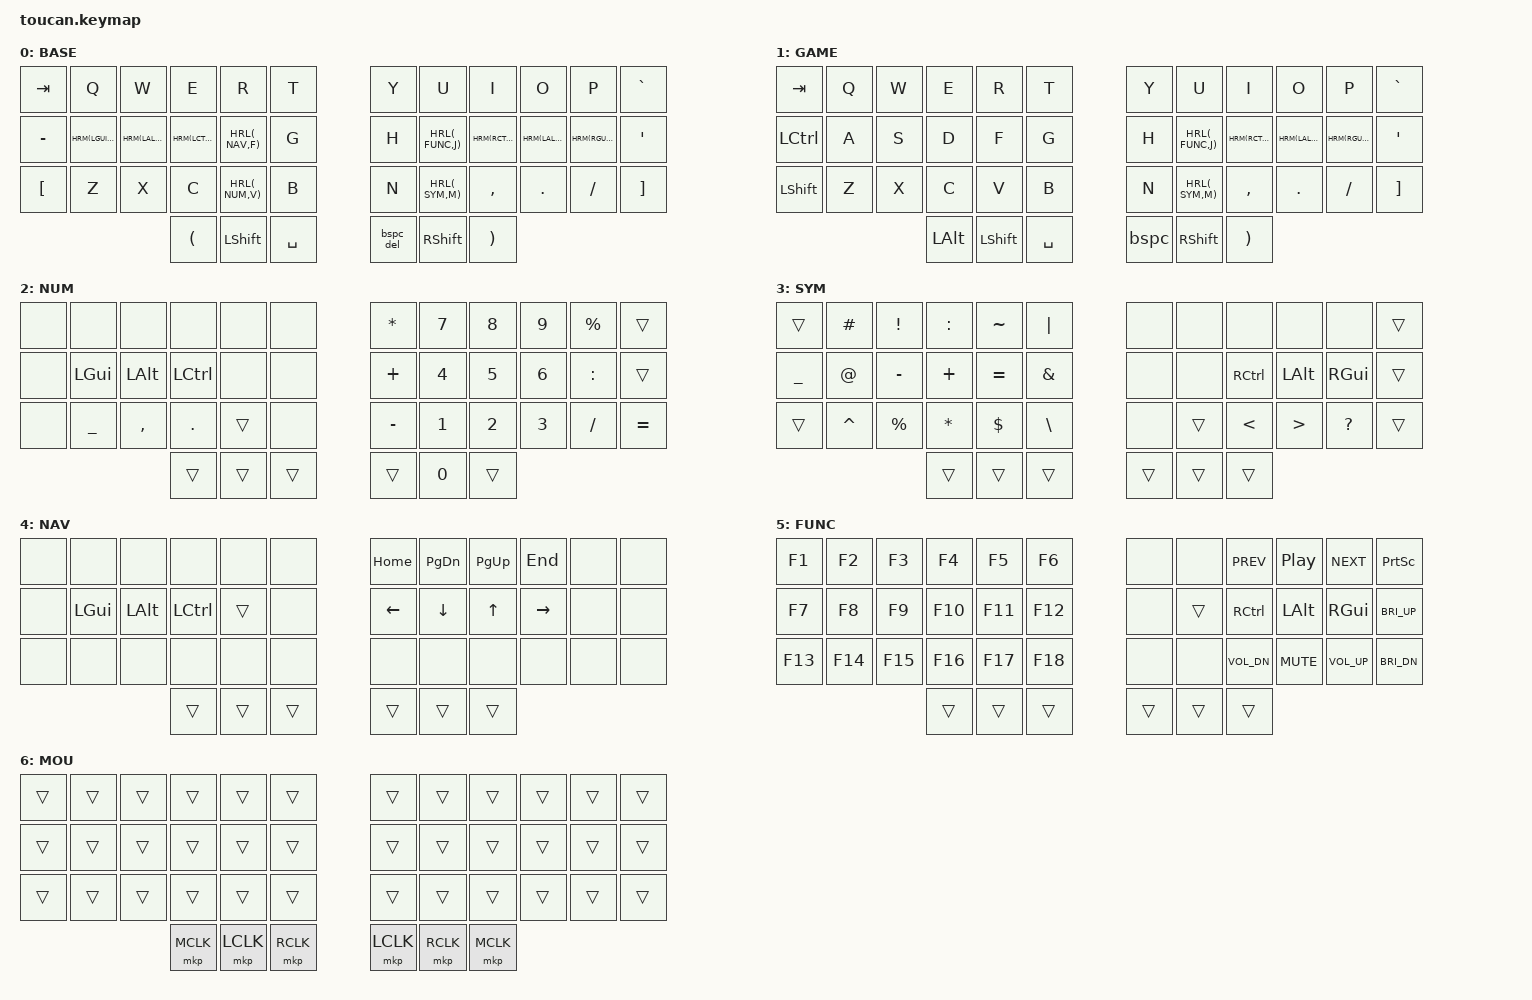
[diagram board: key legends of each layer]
#include <behaviors.dtsi>
#include <dt-bindings/zmk/keys.h>
#include <dt-bindings/zmk/bt.h>
#include <dt-bindings/zmk/outputs.h>
#include <dt-bindings/zmk/pointing.h>

#define _BASE 0
#define _GAM  1
#define _NUM  2
#define _SYM  3
#define _NAV  4
#define _FUNC 5
#define _MOU  6

#define _HRM(m, k) &hrm m k
#define _HRL(l, k) &hrl l k

&caps_word {
    continue-list = <BACKSPACE DELETE UNDERSCORE MINUS>;
};
&lt {
    quick-tap-ms = <170>;
};

/ {
    behaviors {
        bspc_del: backspace_delete {
            compatible = "zmk,behavior-mod-morph";
            #binding-cells = <0>;
            bindings = <&kp BACKSPACE>, <&kp DELETE>;
            mods = <MOD_LSFT>;
        };

        hrm: home_row_mod {
            compatible = "zmk,behavior-hold-tap";
            #binding-cells = <2>;
            flavor = "tap-preferred";
            require-prior-idle-ms = <150>;
            tapping-term-ms = <180>;
            quick-tap-ms = <170>;
            bindings = <&kp>, <&kp>;
            // hold-trigger-key-positions = < ... >; // List of keys on the right side of the keyboard
            // hold-trigger-on-release;
        };
        hrl: home_row_layer {
            compatible = "zmk,behavior-hold-tap";
            #binding-cells = <2>;
            flavor = "tap-preferred";
            require-prior-idle-ms = <150>;
            tapping-term-ms = <180>;
            quick-tap-ms = <170>;
            bindings = <&mo>, <&kp>;
            // hold-trigger-key-positions = < ... >; // List of keys on the right side of the keyboard
            // hold-trigger-on-release;
        };
    };

    // conditional_layers {
    //     compatible = "zmk,conditional-layers";
    //     tri_layer {
    //         if-layers = <1 2>;
    //         then-layer = <3>;
    //     };
    // };

    combos {
        compatible = "zmk,combos";
        combo_esc {
            timeout-ms = <50>;
            require-prior-idle-ms = <100>;
            key-positions = <19 20>;
            bindings = <&kp ESC>;
        };
        combo_ret {
            timeout-ms = <50>;
            require-prior-idle-ms = <100>;
            key-positions = <31 32>;
            bindings = <&kp RET>;
        };
        combo_cw {
            timeout-ms = <50>;
            require-prior-idle-ms = <100>;
            key-positions = <32 33>;
            bindings = <&caps_word>;
        };
        combo_caps {
            timeout-ms = <50>;
            require-prior-idle-ms = <100>;
            key-positions = <33 34>;
            bindings = <&kp CAPS>;
        };
        combo_toggle_game {
            timeout-ms = <50>;
            require-prior-idle-ms = <100>;
            key-positions = <0 5 29>;
            bindings = <&tog 1>;
        };
    };

    keymap {
        compatible = "zmk,keymap";

        base {
            display-name = "BASE";
            bindings = <
//    ┌─────┬──────────────┬──────────────┬──────────────┬──────────────┬─────┐   ┌───────────┬───────────────┬──────────────┬──────────────┬──────────────┬───┐
//    │ tab │      Q       │      W       │      E       │      R       │  T  │   │     Y     │       U       │      I       │      O       │      P       │ ` │
//    ├─────┼──────────────┼──────────────┼──────────────┼──────────────┼─────┤   ├───────────┼───────────────┼──────────────┼──────────────┼──────────────┼───┤
//    │  -  │ _HRM(lgui,A) │ _HRM(lalt,S) │ _HRM(lctl,D) │ _HRL(_NAV,F) │  G  │   │     H     │ _HRL(_FUNC,J) │ _HRM(rctl,K) │ _HRM(lalt,L) │ _HRM(rgui,;) │ ' │
//    ├─────┼──────────────┼──────────────┼──────────────┼──────────────┼─────┤   ├───────────┼───────────────┼──────────────┼──────────────┼──────────────┼───┤
//    │  [  │      Z       │      X       │      C       │ _HRL(_NUM,V) │  B  │   │     N     │ _HRL(_SYM,M)  │      ,       │      .       │      /       │ ] │
//    └─────┴──────────────┴──────────────┼──────────────┼──────────────┼─────┤   ├───────────┼───────────────┼──────────────┼──────────────┴──────────────┴───┘
//                                        │      (       │     lsft     │ spc │   │ &bspc_del │     rsft      │      )       │
//                                        └──────────────┴──────────────┴─────┘   └───────────┴───────────────┴──────────────┘
  &kp TAB     &kp Q          &kp W          &kp E           &kp R          &kp T      &kp Y   &kp U           &kp I           &kp O          &kp P             &kp GRAVE
  &kp MINUS   _HRM(LGUI,A)   _HRM(LALT,S)   _HRM(LCTRL,D)   _HRL(_NAV,F)   &kp G      &kp H   _HRL(_FUNC,J)   _HRM(RCTRL,K)   _HRM(LALT,L)   _HRM(RGUI,SEMI)   &kp SQT
  &kp LBKT    &kp Z          &kp X          &kp C           _HRL(_NUM,V)   &kp B      &kp N   _HRL(_SYM,M)    &kp COMMA       &kp DOT        &kp FSLH          &kp RBKT
  &kp LPAR    &kp LSHFT      &kp SPACE      &bspc_del       &kp RSHFT      &kp RPAR
            >;
        };

        game {
            display-name = "GAME";
            bindings = <
//    ┌──────┬───┬───┬──────┬──────┬─────┐   ┌──────┬───────────────┬────────────────┬──────────────┬──────────────┬───┐
//    │ tab  │ Q │ W │  E   │  R   │  T  │   │  Y   │       U       │       I        │      O       │      P       │ ` │
//    ├──────┼───┼───┼──────┼──────┼─────┤   ├──────┼───────────────┼────────────────┼──────────────┼──────────────┼───┤
//    │ lctl │ A │ S │  D   │  F   │  G  │   │  H   │ _HRL(_FUNC,J) │ _HRM(rctlTL,K) │ _HRM(lalt,L) │ _HRM(rgui,;) │ ' │
//    ├──────┼───┼───┼──────┼──────┼─────┤   ├──────┼───────────────┼────────────────┼──────────────┼──────────────┼───┤
//    │ lsft │ Z │ X │  C   │  V   │  B  │   │  N   │ _HRL(_SYM,M)  │       ,        │      .       │      /       │ ] │
//    └──────┴───┴───┼──────┼──────┼─────┤   ├──────┼───────────────┼────────────────┼──────────────┴──────────────┴───┘
//                   │ lalt │ lsft │ spc │   │ bspc │     rsft      │       )        │
//                   └──────┴──────┴─────┘   └──────┴───────────────┴────────────────┘
  &kp TAB     &kp Q       &kp W       &kp E      &kp R       &kp T      &kp Y   &kp U           &kp I          &kp O          &kp P             &kp GRAVE
  &kp LCTRL   &kp A       &kp S       &kp D      &kp F       &kp G      &kp H   _HRL(_FUNC,J)   _HRM(RCTL,K)   _HRM(LALT,L)   _HRM(RGUI,SEMI)   &kp SQT
  &kp LSHFT   &kp Z       &kp X       &kp C      &kp V       &kp B      &kp N   _HRL(_SYM,M)    &kp COMMA      &kp DOT        &kp FSLH          &kp RBKT
  &kp LALT    &kp LSHFT   &kp SPACE   &kp bspc   &kp RSHFT   &kp RPAR
            >;
        };

        num {
            display-name = "NUM";
            bindings = <
//    ┌─────┬──────┬──────┬──────┬─────┬─────┐   ┌─────┬───┬─────┬───┬───┬─────┐
//    │     │      │      │      │     │     │   │  *  │ 7 │  8  │ 9 │ % │     │
//    ├─────┼──────┼──────┼──────┼─────┼─────┤   ├─────┼───┼─────┼───┼───┼─────┤
//    │     │ lgui │ lalt │ lctl │     │     │   │  +  │ 4 │  5  │ 6 │ : │     │
//    ├─────┼──────┼──────┼──────┼─────┼─────┤   ├─────┼───┼─────┼───┼───┼─────┤
//    │     │  _   │  ,   │  .   │     │     │   │  -  │ 1 │  2  │ 3 │ / │  =  │
//    └─────┴──────┴──────┼──────┼─────┼─────┤   ├─────┼───┼─────┼───┴───┴─────┘
//                        │      │     │     │   │     │ 0 │     │
//                        └──────┴─────┴─────┘   └─────┴───┴─────┘
  &none    &none       &none       &none       &none    &none    &kp STAR    &kp N7   &kp N8   &kp N9   &kp PRCNT   &trans
  &none    &kp LGUI    &kp LALT    &kp LCTRL   &none    &none    &kp PLUS    &kp N4   &kp N5   &kp N6   &kp COLON   &trans
  &none    &kp UNDER   &kp COMMA   &kp DOT     &trans   &none    &kp MINUS   &kp N1   &kp N2   &kp N3   &kp FSLH    &kp EQUAL
  &trans   &trans      &trans      &trans      &kp N0   &trans
            >;
        };

        sym {
            display-name = "SYM";
            bindings = <
//    ┌─────┬───┬───┬─────┬─────┬─────┐   ┌─────┬─────┬──────┬──────┬──────┬─────┐
//    │     │ # │ ! │  :  │  ~  │  |  │   │     │     │      │      │      │     │
//    ├─────┼───┼───┼─────┼─────┼─────┤   ├─────┼─────┼──────┼──────┼──────┼─────┤
//    │  _  │ @ │ - │  +  │  =  │  &  │   │     │     │ rctl │ lalt │ rgui │     │
//    ├─────┼───┼───┼─────┼─────┼─────┤   ├─────┼─────┼──────┼──────┼──────┼─────┤
//    │     │ ^ │ % │  *  │  $  │  \  │   │     │     │  <   │  >   │  ?   │     │
//    └─────┴───┴───┼─────┼─────┼─────┤   ├─────┼─────┼──────┼──────┴──────┴─────┘
//                  │     │     │     │   │     │     │      │
//                  └─────┴─────┴─────┘   └─────┴─────┴──────┘
  &trans      &kp HASH    &kp EXCL    &kp COLON   &kp TILDE   &kp PIPE   &none   &none    &none       &none      &none       &trans
  &kp UNDER   &kp AT      &kp MINUS   &kp PLUS    &kp EQUAL   &kp AMPS   &none   &none    &kp RCTRL   &kp LALT   &kp RGUI    &trans
  &trans      &kp CARET   &kp PRCNT   &kp STAR    &kp DLLR    &kp BSLH   &none   &trans   &kp LT      &kp GT     &kp QMARK   &trans
  &trans      &trans      &trans      &trans      &trans      &trans
            >;
        };

        nav {
            display-name = "NAV";
            bindings = <
//    ┌─────┬──────┬──────┬──────┬─────┬─────┐   ┌──────┬──────┬──────┬──────┬─────┬─────┐
//    │     │      │      │      │     │     │   │ home │ pgdn │ pgup │ end  │     │     │
//    ├─────┼──────┼──────┼──────┼─────┼─────┤   ├──────┼──────┼──────┼──────┼─────┼─────┤
//    │     │ lgui │ lalt │ lctl │     │     │   │ left │ down │  up  │ rght │     │     │
//    ├─────┼──────┼──────┼──────┼─────┼─────┤   ├──────┼──────┼──────┼──────┼─────┼─────┤
//    │     │      │      │      │     │     │   │      │      │      │      │     │     │
//    └─────┴──────┴──────┼──────┼─────┼─────┤   ├──────┼──────┼──────┼──────┴─────┴─────┘
//                        │      │     │     │   │      │      │      │
//                        └──────┴─────┴─────┘   └──────┴──────┴──────┘
  &none    &none      &none      &none       &none    &none    &kp HOME   &kp PG_DN   &kp PG_UP   &kp END     &none   &none
  &none    &kp LGUI   &kp LALT   &kp LCTRL   &trans   &none    &kp LEFT   &kp DOWN    &kp UP      &kp RIGHT   &none   &none
  &none    &none      &none      &none       &none    &none    &none      &none       &none       &none       &none   &none
  &trans   &trans     &trans     &trans      &trans   &trans
            >;
        };

        func {
            display-name = "FUNC";
            bindings = <
//    ┌─────┬─────┬─────┬─────┬─────┬─────┐   ┌─────┬─────┬──────┬──────┬──────┬──────┐
//    │ f1  │ f2  │ f3  │ f4  │ f5  │ f6  │   │     │     │ prev │ play │ next │ pscr │
//    ├─────┼─────┼─────┼─────┼─────┼─────┤   ├─────┼─────┼──────┼──────┼──────┼──────┤
//    │ f7  │ f8  │ f9  │ f10 │ f11 │ f12 │   │     │     │ rctl │ lalt │ rgui │ bri+ │
//    ├─────┼─────┼─────┼─────┼─────┼─────┤   ├─────┼─────┼──────┼──────┼──────┼──────┤
//    │ f13 │ f14 │ f15 │ f16 │ f17 │ f18 │   │     │     │ vold │ mute │ volu │ bri- │
//    └─────┴─────┴─────┼─────┼─────┼─────┤   ├─────┼─────┼──────┼──────┴──────┴──────┘
//                      │     │     │     │   │     │     │      │
//                      └─────┴─────┴─────┘   └─────┴─────┴──────┘
  &kp F1    &kp F2    &kp F3    &kp F4    &kp F5    &kp F6    &none   &none    &kp C_PREV     &kp C_PP     &kp C_NEXT     &kp PRINTSCREEN
  &kp F7    &kp F8    &kp F9    &kp F10   &kp F11   &kp F12   &none   &trans   &kp RCTRL      &kp LALT     &kp RGUI       &kp C_BRI_UP
  &kp F13   &kp F14   &kp F15   &kp F16   &kp F17   &kp F18   &none   &none    &kp C_VOL_DN   &kp C_MUTE   &kp C_VOL_UP   &kp C_BRI_DN
  &trans    &trans    &trans    &trans    &trans    &trans
            >;
        };

        mouse {
            display-name = "MOU";
            bindings = <
//    ┌─────┬─────┬─────┬──────┬──────┬──────┐   ┌──────┬──────┬──────┬─────┬─────┬─────┐
//    │     │     │     │      │      │      │   │      │      │      │     │     │     │
//    ├─────┼─────┼─────┼──────┼──────┼──────┤   ├──────┼──────┼──────┼─────┼─────┼─────┤
//    │     │     │     │      │      │      │   │      │      │      │     │     │     │
//    ├─────┼─────┼─────┼──────┼──────┼──────┤   ├──────┼──────┼──────┼─────┼─────┼─────┤
//    │     │     │     │      │      │      │   │      │      │      │     │     │     │
//    └─────┴─────┴─────┼──────┼──────┼──────┤   ├──────┼──────┼──────┼─────┴─────┴─────┘
//                      │ mclk │ lclk │ rclk │   │ lclk │ rclk │ mclk │
//                      └──────┴──────┴──────┘   └──────┴──────┴──────┘
  &trans      &trans      &trans      &trans      &trans      &trans      &trans   &trans   &trans   &trans   &trans   &trans
  &trans      &trans      &trans      &trans      &trans      &trans      &trans   &trans   &trans   &trans   &trans   &trans
  &trans      &trans      &trans      &trans      &trans      &trans      &trans   &trans   &trans   &trans   &trans   &trans
  &mkp MCLK   &mkp LCLK   &mkp RCLK   &mkp LCLK   &mkp RCLK   &mkp MCLK
            >;
        };

    };
};
